# CY8C4245AXI_483 register map
File version: 0.1
PSoC 4200
Registers are 32-bit, read-write, no defined reset value unless marked. A register's access mark holds for its fields unless they carry their own. Offsets are from the block's base; lines under a group give offsets from that group; [hi:lo] are bit positions; {n}, {i} and the like mark numbered series; 'fields as' and 'values as' point back to an identical list; <NAME> marks a mode.

## Memory map
0x00000000 ADC — Sequencing SAR ADC
0x00000000 Comp_1 — Low Power Comparator
0x00000000 CapSense_IDAC1 — IDAC
0x00000000 CapSense_IDAC2 — IDAC
0x00000000 ADC_2_Buffer — OpAmp
0x00000000 ADC_3_Buffer — OpAmp
0x00000000 Timer
0x00000000 PWM_0
0x00000000 UART — Serial Communication Block
0x00000000 I2C — Serial Communication Block
0x00000000 PWM_2
0x00000000 PWM_1
0x00000000 Comp_0 — Low Power Comparator

## Comp_1 — Low Power Comparator
Base 0x00000000
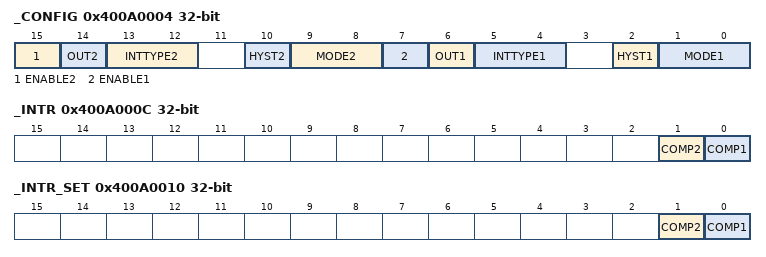
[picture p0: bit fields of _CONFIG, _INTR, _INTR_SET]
0x400A0004 _CONFIG — LPCOMP configuration
  [15] ENABLE2 — Enable comparator #2
    0=DISABLE (Comparator disabled); 1=ENABLE (Comparator enabled)
  [14] OUT2 ro — Current output value of the comparator #2
  [13:12] INTTYPE2 — Sets which edge will trigger an IRQ for the comparator #2
    0=DISABLE (Disabled); 1=RISING (Rising edge); 2=FALLING (Falling edge); 3=BOTH (Both rising and falling edges)
  [10] HYST2 — Selects hysteresis (10mV) for the comparator #2
    0=ENABLE (Hysteresis enabled); 1=DISABLE (Hysteresis disabled)
  [9:8] MODE2 — Selects speed for the comparator #2
    0=MED (Medium speed); 1=FAST (Fast speed); 2=SLOW (Slow speed)
  [7] ENABLE1 — Enable comparator #1
    values as ENABLE2
  [6] OUT1 ro — Current output value of the comparator
  [5:4] INTTYPE1 — Sets which edge will trigger an IRQ for the comparator #1
    values as INTTYPE2
  [2] HYST1 — Selects hysteresis (10mV) for the comparator #1
    values as HYST2
  [1:0] MODE1 — Selects speed for the comparator #1
    values as MODE2
0x400A000C _INTR — LPCOMP interrupt
  [1] COMP2 — Comparator #2 Interrupt: hardware sets this interrupt when comparator 0 triggers. Write with '1' to clear bit.
  [0] COMP1 — Comparator #1 Interrupt: hardware sets this interrupt when comparator 0 triggers. Write with '1' to clear bit.
0x400A0010 _INTR_SET — LPCOMP interrupt set register
  [1] COMP2 — Write with '1' to set corresponding bit in interrupt request register.
  [0] COMP1 — Write with '1' to set corresponding bit in interrupt request register.
0x400AFF08 _TRIM_A — LPCOMP trim A
0x400AFF0C _TRIM_B — LPCOMP trim B

## Comp_0 — Low Power Comparator
Base 0x00000000
Registers as Comp_1, without _TRIM_A, _TRIM_B; these are added or differ:
0x400AFF00 _TRIM_A — LPCOMP trim A
0x400AFF04 _TRIM_B — LPCOMP trim B

## CapSense_IDAC1 — IDAC
Base 0x00000000
Same registers: CapSense_IDAC2 0x00000000
0x40080004 CSD_IDAC_POLARITY
0x40080008 CSD_IDAC
0x4008FF00 CSD_TRIM1 — CSD IDAC TRIM1
0x4008FF04 CSD_TRIM2 — CSD IDAC TRIM2

## ADC_2_Buffer — OpAmp
Base 0x00000000
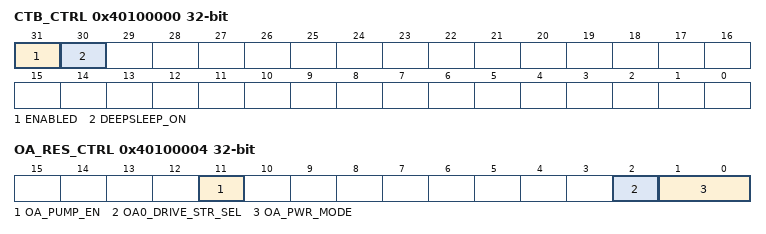
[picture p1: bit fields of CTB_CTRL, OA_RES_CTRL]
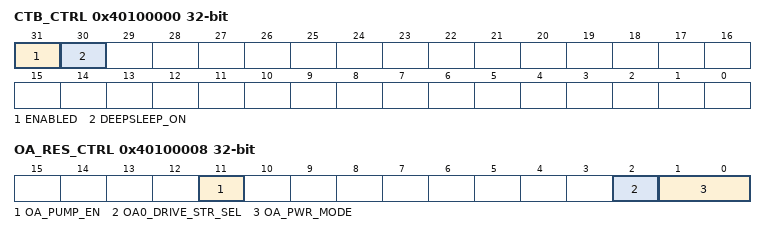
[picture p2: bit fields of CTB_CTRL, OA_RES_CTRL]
0x40100000 CTB_CTRL — Global CTB IP and power control
  [31] ENABLED — Selects component behavior in DeepSleep power mode
    0=DISABLE (CTB IP disabled (put analog in power down, open all switches)); 1=ENABLE (CTB IP enabledCTB IP enabled)
  [30] DEEPSLEEP_ON — Selects component behavior in DeepSleep power mode
    0=DISABLE (CTB IP disabled off during DeepSleep power mode); 1=ENABLE (CTB IP remains enabled during DeepSleep power mode (if ENABLED=1))
0x40100004 OA_RES_CTRL — Opamp and resistor control
  [11] OA_PUMP_EN — Selects pump
    0=DISABLE (Pump disabled); 1=ENABLE (Pump enabled)
  [2] OA0_DRIVE_STR_SEL — Opamp output strenght select
    0=Internal only; 1=Output to pin
  [1:0] OA_PWR_MODE — Selects power for opamp
    0=OFF; 1=LOW (Low power); 2=MED (Medium power); 3=HIGH (High power)
0x40100F08 OA_COMP_TRIM — Opamp Compenation Capacitor Trim
  [1:0] OA_COMP_TRIM
    1=HIGH_SPEED; 2=BALANCED; 3=HIGH_STABILITY

## ADC_3_Buffer — OpAmp
Base 0x00000000
0x40100000 CTB_CTRL — Global CTB IP and power control
  [31] ENABLED — Selects component behavior in DeepSleep power mode
    0=DISABLE (CTB IP disabled (put analog in power down, open all switches)); 1=ENABLE (CTB IP enabledCTB IP enabled)
  [30] DEEPSLEEP_ON — Selects component behavior in DeepSleep power mode
    0=DISABLE (CTB IP disabled off during DeepSleep power mode); 1=ENABLE (CTB IP remains enabled during DeepSleep power mode (if ENABLED=1))
0x40100008 OA_RES_CTRL — Opamp and resistor control
  [11] OA_PUMP_EN — Selects pump
    0=DISABLE (Pump disabled); 1=ENABLE (Pump enabled)
  [2] OA0_DRIVE_STR_SEL — Opamp output strenght select
    0=Internal only; 1=Output to pin
  [1:0] OA_PWR_MODE — Selects power for opamp
    0=OFF; 1=LOW (Low power); 2=MED (Medium power); 3=HIGH (High power)
0x40100F14 OA_COMP_TRIM — Opamp Compenation Capacitor Trim
  [1:0] OA_COMP_TRIM
    1=HIGH_SPEED; 2=BALANCED; 3=HIGH_STABILITY
